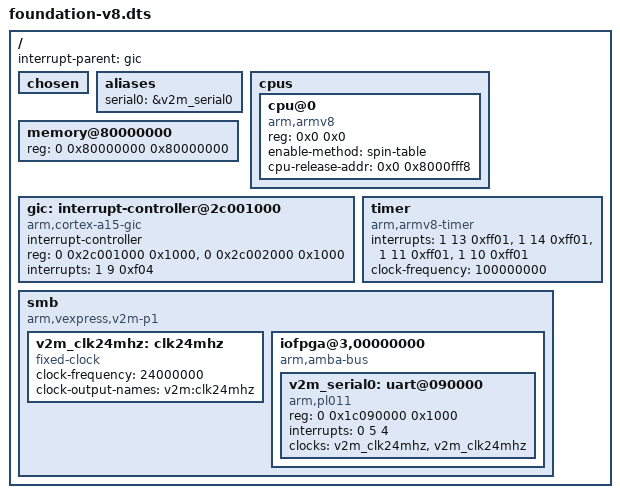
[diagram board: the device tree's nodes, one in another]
/*
 * ARM Ltd.
 *
 * ARMv8 Foundation model DTS
 */

/dts-v1/;

/memreserve/ 0x80000000 0x00010000;

/ {
	interrupt-parent = <&gic>;
	#address-cells = <2>;
	#size-cells = <1>;

	chosen { };

	aliases {
		serial0 = &v2m_serial0;
	};

	cpus {
		#address-cells = <2>;
		#size-cells = <0>;

		cpu@0 {
			device_type = "cpu";
			compatible = "arm,armv8";
			reg = <0x0 0x0>;
			enable-method = "spin-table";
			cpu-release-addr = <0x0 0x8000fff8>;
		};
	};

	memory@80000000 {
		device_type = "memory";
		reg = <0 0x80000000 0x80000000>;
	};

	gic: interrupt-controller@2c001000 {
		compatible = "arm,cortex-a15-gic", "arm,cortex-a9-gic";
		#interrupt-cells = <3>;
		#address-cells = <0>;
		interrupt-controller;
		reg = <0 0x2c001000 0x1000>,
		      <0 0x2c002000 0x1000>;
		interrupts = <1 9 0xf04>;
	};

	timer {
		compatible = "arm,armv8-timer";
		interrupts = <1 13 0xff01>,
			     <1 14 0xff01>,
			     <1 11 0xff01>,
			     <1 10 0xff01>;
		clock-frequency = <100000000>;
	};

	smb {
		compatible = "arm,vexpress,v2m-p1", "simple-bus";
		/*arm,v2m-memory-map = "rs1";*/
		#address-cells = <2>;
		#size-cells = <1>;
		ranges;

		v2m_clk24mhz: clk24mhz {
			compatible = "fixed-clock";
			#clock-cells = <0>;
			clock-frequency = <24000000>;
			clock-output-names = "v2m:clk24mhz";
		};

		iofpga@3,00000000 {
			compatible = "arm,amba-bus", "simple-bus";
			#address-cells = <2>;
			#size-cells = <1>;
			ranges;

			v2m_serial0: uart@090000 {
				compatible = "arm,pl011", "arm,primecell";
				reg = <0 0x1c090000 0x1000>;
				interrupts = <0 5 4>;
				clocks = <&v2m_clk24mhz>, <&v2m_clk24mhz>;
				clock-names = "uartclk", "apb_pclk";
			};
		};
	};
};
